# PIC32MZ0512EFK144 device description
Architecture: MIPS; Family: PIC32MZEF; Series: PIC32MZ
Registers are 32-bit, read-write, no defined reset value unless marked. A register's access mark holds for its fields unless they carry their own. Offsets are from the block's base; [hi:lo] are bit positions.

## CRYPTO
Instances: CRYPTO 0x1f8e5000 in periph_indep
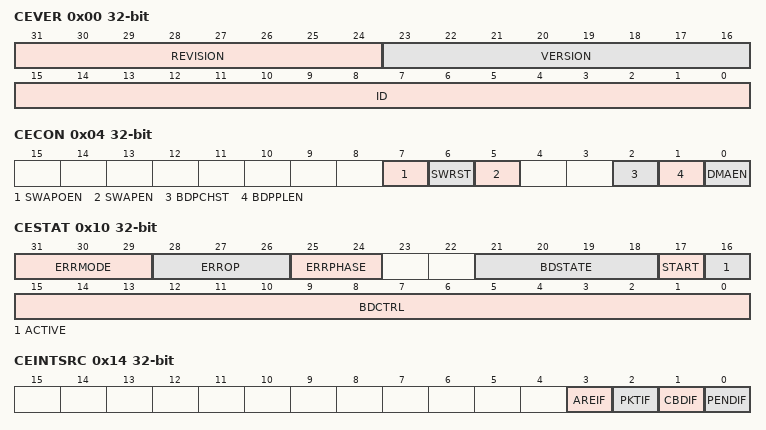
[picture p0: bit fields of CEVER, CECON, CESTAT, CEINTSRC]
0x00 CEVER ro — Crypto Engine Revision
  [31:24] REVISION, [23:16] VERSION, [15:0] ID
0x04 CECON — Crypto Engine Control Register
  [7] SWAPOEN — Swap Output Data Enable bit
    1=Output data is byte swapped when written by dedicated DMA; 0=Output data is not byte swapped when written by dedicated DMA
  [6] SWRST — Software Reset bit
    1=Initiate a software reset of the Crypto Engine; 0=Normal operation
  [5] SWAPEN — Input Data Swap Enable bit
    1=Input data is byte swapped when read by dedicated DMA; 0=Input data is not byte swapped when read by dedicated DMA
  [2] BDPCHST — Buffer Descriptor Processor Fetch Enable bit
    1=BDP descriptor fetch is enabled; 0=BDP descriptor fetch is disabled
  [1] BDPPLEN — Buffer Descriptor Processor Poll Enable bit
    1=Poll for descriptor until valid bit is set; 0=Do not poll
  [0] DMAEN — DMA Enable bit
    1=Crypto Engine DMA is enabled; 0=Crypto Engine DMA is disabled
0x08 CEBDADDR ro — Crypto Engine Buffer Descriptor Register
  [31:0] BDPADDR
0x0C CEBDPADDR ro — Crypto Engine Buffer Descriptor Processor Register
  [31:0] BASEADDR
0x10 CESTAT ro — Crypto Engine Status Register
  [31:29] ERRMODE — Internal Error Mode Status bits
    3=CEK operation; 2=KEK operation; 1=Preboot authentication; 0=Normal operation
  [28:26] ERROP — Internal Error Operation Status bits
    4=Authentication; 2=Decryption; 1=Encryption
  [25:24] ERRPHASE — Internal Error Phase of DMA Status bits
    3=Destination data; 2=Source data; 1=Security Association (SA) access; 0=Buffer Descriptor (BD) access
  [21:18] BDSTATE — Buffer Descriptor Processor State Status bits
    6=SA fetch; 5=Fetch BDP is disabled; 4=Descriptor is done; 3=Data phase; 2=BDP is loading; 1=Descriptor fetch request is pending; 0=BDP is idle
  [17] START — DMA Start Status bit
    1=DMA start has occurred; 0=DMA start has not occurred
  [16] ACTIVE — Buffer Descriptor Processor Status bit
    1=BDP is active; 0=BDP is idle
  [15:0] BDCTRL
0x14 CEINTSRC ro — Crypto Engine Interrupt Source Register
  [3] AREIF — Access Response Error Interrupt bit
    1=Error occurred trying to access memory outside the Crypto Engine; 0=No error has occurred
  [2] PKTIF — DMA Packet Completion Interrupt Status bit
    1=DMA packet was completed; 0=DMA packet was not completed
  [1] CBDIF — BD Transmit Status bit
    1=Last BD transmit was processed; 0=Last BD transmit has not been processed
  [0] PENDIF — Crypto Engine Interrupt Pending Status bit
    1=Crypto Engine interrupt is pending (this value is the result of an OR of all interrupts in the Crypto Engine); 0=Crypto Engine interrupt is not pending
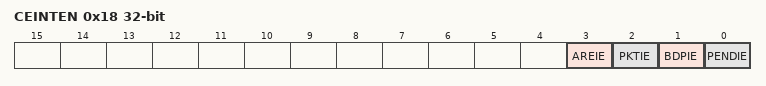
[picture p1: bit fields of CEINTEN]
0x18 CEINTEN — Crypto Engine Interrupt Enable Register
  [3] AREIE — Access Response Error Interrupt Enable bit
    1=Access response error interrupts are enabled; 0=Access response error interrupts are not enabled
  [2] PKTIE — DMA Packet Completion Interrupt Enable bit
    1=DMA packet completion interrupts are enabled; 0=DMA packet completion interrupts are not enabled
  [1] BDPIE — DMA Buffer Descriptor Processor Interrupt Enable bit
    1=BDP interrupts are enabled; 0=BDP interrupts are not enabled
  [0] PENDIE — Master Interrupt Enable bit
    1=Crypto Engine interrupts are enabled; 0=Crypto Engine interrupts are not enabled
0x1C CEPOLLCON — Crypto Engine Poll Control Register
  [15:0] BDPPLCON
0x20 CEHDLEN — Crypto Engine Header Length Register
  [7:0] HDRLEN
0x24 CETRLLEN — Crypto Engine Trailer Length Register
  [7:0] TRLRLEN

## CVR
Instances: CVR 0x1f800e00 in periph_pb1_std
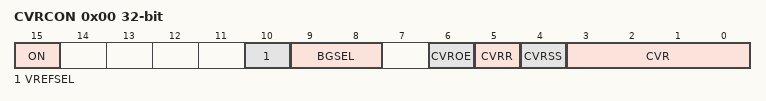
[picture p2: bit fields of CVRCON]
0x00 CVRCON — Comparator Voltage Reference Control Register
  [15] ON — Comparator Voltage Reference On bit
    1=Module is enabled. Setting this bit does not affect other bits in the register.; 0=Module is disabled and does not consume current. Clearing this bit does not affect the other bits in the register.
  [10] VREFSEL
  [9:8] BGSEL
  [6] CVROE — CVrefout Enable bit
    1=Voltage level is output on CVrefout pin; 0=Voltage level is disconnected from CVrefout pin
  [5] CVRR — CVref Range Selection bit
    1=0 to 0.67 CVrsrc; 0=0.25 CVrsrc to 0.75 CVrsrc
  [4] CVRSS — CVref Source Selection bit
    1=Comparator voltage reference source, CVRSRC = (VREF+) - (VREF-); 0=Comparator voltage reference source, CVRSRC = AVDD - AVSS
  [3:0] CVR

## Notices in the file
Copyright (c) 2017 Microchip Technology Inc.
SPDX-License-Identifier: Apache-2.0
Licensed under the Apache License, Version 2.0 (the "License");
you may not use this file except in compliance with the License.
You may obtain a copy of the License at
http://www.apache.org/licenses/LICENSE-2.0
Unless required by applicable law or agreed to in writing, software
distributed under the License is distributed on an "AS IS" BASIS,
WITHOUT WARRANTIES OR CONDITIONS OF ANY KIND, either express or implied.
See the License for the specific language governing permissions and
limitations under the License.
